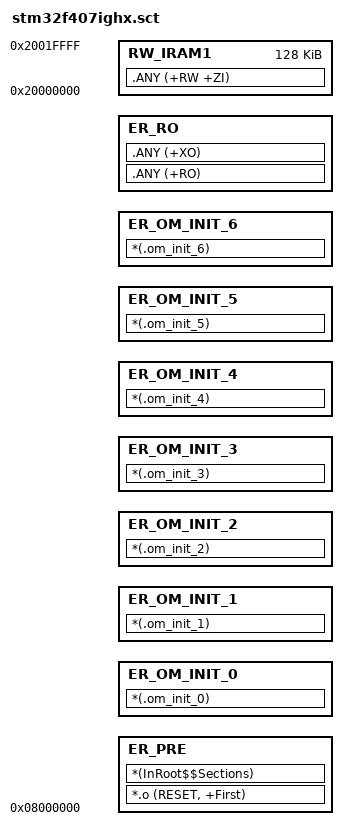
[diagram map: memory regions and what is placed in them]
; *************************************************************
; *** Scatter-Loading Description File generated by uVision ***
; *************************************************************
; 修改：
;   ER_PRE       —— RESET / InRoot$$Sections（向量表 + C 运行时）
;   ER_OM_INIT_0..6 —— .om_init_<N>（每级一段，按级别顺序排列，级别顺序由链接器保证；
;                 armlink 自动生成 Image$$ER_OM_INIT_<N>$$Base/Limit，
;                 由 om_init.c 内 extern 引用）
;   ER_RO        —— 其余 RO/RW/ZI 数据

LR_IROM1 0x08000000 0x00200000  {    ; load region size_region
  ER_PRE 0x08000000  {               ; 向量表 + C 运行时库
   *.o (RESET, +First)
   *(InRoot$$Sections)
  }
  ER_OM_INIT_0 +0  {                 ; OM_INIT 0 级（EARLIEST）回调表
   *(.om_init_0)
  }
  ER_OM_INIT_1 +0  {                 ; OM_INIT 1 级（BOARD）
   *(.om_init_1)
  }
  ER_OM_INIT_2 +0  {                 ; OM_INIT 2 级（DRIVER）
   *(.om_init_2)
  }
  ER_OM_INIT_3 +0  {                 ; OM_INIT 3 级（SERVICE）
   *(.om_init_3)
  }
  ER_OM_INIT_4 +0  {                 ; OM_INIT 4 级（SYSTEM）
   *(.om_init_4)
  }
  ER_OM_INIT_5 +0  {                 ; OM_INIT 5 级（APPLICATION）
   *(.om_init_5)
  }
  ER_OM_INIT_6 +0  {                 ; OM_INIT 6 级（LATE）
   *(.om_init_6)
  }
  ER_RO +0  {                        ; 其余只读数据 + 代码
   .ANY (+RO)
   .ANY (+XO)
  }
  RW_IRAM1 0x20000000 0x00020000  {  ; RW data
   .ANY (+RW +ZI)
  }
}
